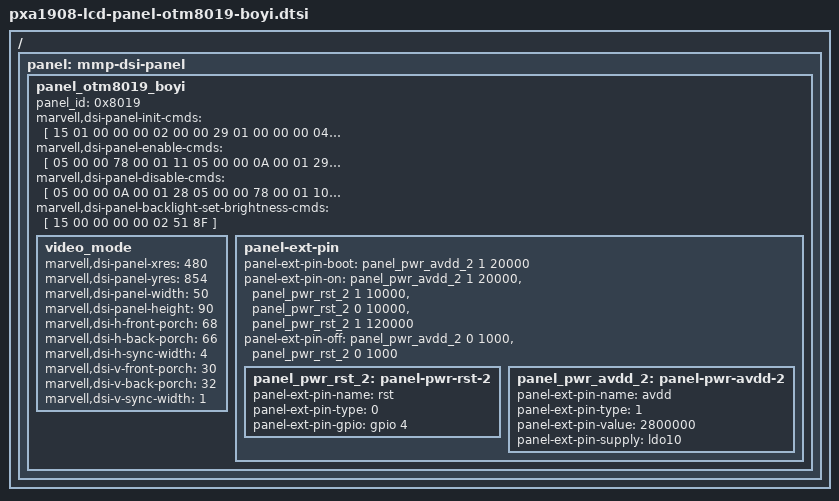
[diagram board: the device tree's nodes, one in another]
/*
 *  Copyright (C) 2014 Marvell Technology Group Ltd.
 *  Author: Hongyan Song <hysong@marvell.com>
 *
 *  This program is free software; you can redistribute it and/or modify
 *  it under the terms of the GNU General Public License version 2 as
 *  publishhed by the Free Software Foundation.
 */

/ {
	panel: mmp-dsi-panel {
		panel_otm8019_boyi {
			panel_id = <0x8019>;
			/*
	                 * DSI PACKET HEADER INFO
	                 * @ data type :  1byte
	                 * @ command type : 1byte
	                 * @ delay(msec) : 2byte
	                 * @ size of data : 2byte
	                 */
	                marvell,dsi-panel-init-cmds = [
				15 01 00 00 00 02 00 00
				29 01 00 00 00 04 FF 80 19 01
				15 01 00 00 00 02 00 80
				29 01 00 00 00 03 FF 80 19
				15 01 00 00 00 02 00 80
				29 01 00 00 00 02 C4 30
				15 01 00 00 00 02 00 8A
				29 01 00 00 00 02 C4 40
				15 01 00 00 00 02 00 C6
				29 01 00 00 00 02 b0 03
				15 01 00 00 00 02 00 90
				29 01 00 00 00 02 b3 02
				15 01 00 00 00 02 00 92
				29 01 00 00 00 02 b3 45
				15 01 00 00 00 02 00 a2
				29 01 00 00 00 04 C0 04 00 02
				15 01 00 00 00 02 00 80
				29 01 00 00 00 06 C0 00 58 00 14 16
				15 01 00 00 00 02 00 90
				29 01 00 00 00 07 C0 00 15 00 00 00 03
				15 01 00 00 00 02 00 b4
				29 01 00 00 00 02 c0 00
				15 01 00 00 00 02 00 81
				29 01 00 00 00 02 C1 33
				15 01 00 00 00 02 00 A1
				29 01 00 00 00 02 C1 0E
				15 01 00 00 00 02 00 80
				29 01 00 00 00 03 C4 30 83
				15 01 00 00 00 02 00 89
				29 01 00 00 00 02 C4 08
				15 01 00 00 00 02 00 82
				29 01 00 00 00 02 C5 B0
				15 01 00 00 00 02 00 90
				29 01 00 00 00 05 C5 4E 76 01 03
				15 01 00 00 00 02 00 B1
				29 01 00 00 00 02 C5 A9
				15 01 00 00 00 02 00 80
				29 01 00 00 00 0D CE 87 03 00 85 03 00 86 03 00 84 03 00
				15 01 00 00 00 02 00 A0
				29 01 00 00 00 0F CE 38 03 03 58 00 00 00 38 02 03 59 00 00 00
				15 01 00 00 00 02 00 B0
				29 01 00 00 00 0F CE 38 01 03 5A 00 00 00 38 00 03 5B 00 00 00
				15 01 00 00 00 02 00 C0
				29 01 00 00 00 0F CE 30 00 03 5C 00 00 00 30 01 03 5D 00 00 00
				15 01 00 00 00 02 00 D0
				29 01 00 00 00 0F CE 30 02 03 5E 00 00 00 30 03 03 5F 00 00 00
				15 01 00 00 00 02 00 C7
				29 01 00 00 00 02 CF 00
				15 01 00 00 00 02 00 C9
				29 01 00 00 00 02 CF 00
				15 01 00 00 00 02 00 C4
				29 01 00 00 00 07 CB 01 01 01 01 01 01
				15 01 00 00 00 02 00 D9
				29 01 00 00 00 07 CB 00 00 01 01 01 01
				15 01 00 00 00 02 00 E0
				29 01 00 00 00 03 CB 01 01
				15 01 00 00 00 02 00 84
				29 01 00 00 00 07 CC 0C 0A 10 0E 03 04
				15 01 00 00 00 02 00 9E
				29 01 00 00 00 02 CC 00
				15 01 00 00 00 02 00 A0
				29 01 00 00 00 08 CC 00 02 01 0d 0f 09 0b
				15 01 00 00 00 02 00 B4
				29 01 00 00 00 07 CC 0D 0F 09 0B 02 01
				15 01 00 00 00 02 00 CE
				29 01 00 00 00 02 CC 85
				15 01 00 00 00 02 00 D0
				29 01 00 00 00 08 CC 05 03 04 0c 0a 10 0e
				15 01 00 00 00 02 00 00
				29 01 00 00 00 03 D8 75 75
				15 01 00 00 00 02 00 00
				29 01 00 00 00 02 D9 62
				15 01 00 00 00 02 00 00
				29 01 00 00 00 15 E1 00 06 0c 1e 33 4b 55 88 78 8e 78 67 81 6d 73 6c 65 56 4e 00
				15 01 00 00 00 02 00 00
				29 01 00 00 00 15 E2 00 06 0c 1e 33 4b 55 87 78 8e 78 68 80 6d 72 6b 65 57 4e 00
				15 01 00 00 00 02 00 98
				29 01 00 00 00 02 c0 00
				15 01 00 00 00 02 00 a9
				29 01 00 00 00 02 c0 06
				15 01 00 00 00 02 00 b0
				29 01 00 00 00 04 C1 20 00 00
				15 01 00 00 00 02 00 e1
				29 01 00 00 00 03 C0 40 18
				15 01 00 00 00 02 00 80
				29 01 00 00 00 02 c4 30
				15 01 00 00 00 02 00 80
				29 01 00 00 00 03 C1 03 33
				15 01 00 00 00 02 00 a0
				29 01 00 00 00 02 C1 e8
				15 01 00 00 00 02 00 90
				29 01 00 00 00 02 b6 b4
				15 01 00 00 00 02 00 00
				29 01 00 00 00 04 FF FF FF FF
				15 01 00 00 00 02 51 00
				15 01 00 00 00 02 53 24
			];
			marvell,dsi-panel-enable-cmds = [
	                        05 00 00 78 00 01       11
	                        05 00 00 0A 00 01       29
	                ];
	                marvell,dsi-panel-disable-cmds = [
	                        05 00 00 0A 00 01       28
	                        05 00 00 78 00 01       10
	                ];
			/*
	                 * BACKLIGHT CONTROL BY PANEL
	                 */
	                marvell,dsi-panel-backlight-set-brightness-cmds = [
	                        15 00 00 00 00 02       51 8F
	                ];
			video_mode {
	                        marvell,dsi-panel-xres = <480>;
	                        marvell,dsi-panel-yres = <854>;
	                        marvell,dsi-panel-width= <50>;      /* screen width in mm */
	                        marvell,dsi-panel-height = <90>;    /* screen height in mm */
	                        marvell,dsi-h-front-porch = <68>;   /* right margin */
	                        marvell,dsi-h-back-porch = <66>;    /* left margin */
	                        marvell,dsi-h-sync-width = <4>;    /* hsync len */
	                        marvell,dsi-v-front-porch = <30>;    /* lower margin */
	                        marvell,dsi-v-back-porch = <32>;    /* upper margin */
	                        marvell,dsi-v-sync-width = <1>;     /* vsync len */
	                };
			 panel-ext-pin {
	                        /*
	                         * Three properties are required
	                         * to control pwr pin
	                         * @node : panel-ext-pin node
	                         * @on : <0> - off / <1> - on
	                         * @usec : delay time of usec
	                         */
	                         /*
	                         * panel-ext-pin-boot sequence
	                         * is skip power on mode
	                         */
	                        panel-ext-pin-boot = <
	                                &panel_pwr_avdd_2  1 20000
	                        >;
	                        panel-ext-pin-on = <
	                                &panel_pwr_avdd_2  1 20000
	                                &panel_pwr_rst_2   1 10000
	                                &panel_pwr_rst_2   0 10000
	                                &panel_pwr_rst_2   1 120000
	                        >;
	                        panel-ext-pin-off = <
	                                &panel_pwr_avdd_2  0 1000
					&panel_pwr_rst_2   0 1000
	                        >;
	                        /*
	                         * There are four properties to define pwr pin
	                         * <prefix>-name : pin name
	                         * <prefix>-type : <0> - GPIO, <1> - PMIC Regulator
	                         * <prefix>-gpio : If the type is GPIO, assign a gpio.
	                         * <prefix>-supply : If the type is PMIC Regulator, assign a regulator.
	                         */
	                        panel_pwr_rst_2: panel-pwr-rst-2 {
	                                panel-ext-pin-name = "rst";
	                                panel-ext-pin-type = <0>;
	                                panel-ext-pin-gpio = <&gpio 4 0>;
	                        };
	                        panel_pwr_avdd_2: panel-pwr-avdd-2 {
	                                panel-ext-pin-name = "avdd";
	                                panel-ext-pin-type = <1>;
					panel-ext-pin-value = <2800000>;
	                                panel-ext-pin-supply = <&ldo10>;
	                        };
	                };
		};
	};
};
